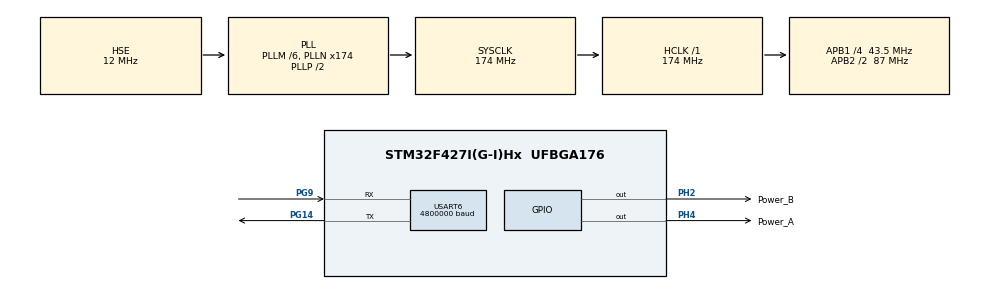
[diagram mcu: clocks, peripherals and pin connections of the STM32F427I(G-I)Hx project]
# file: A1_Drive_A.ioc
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Dma.Request0=USART6_TX
Dma.Request1=USART6_RX
Dma.USART6_RX.1.Direction=DMA_PERIPH_TO_MEMORY
Dma.USART6_RX.1.FIFOMode=DMA_FIFOMODE_DISABLE
Dma.USART6_RX.1.Instance=DMA2_Stream2
Dma.USART6_RX.1.MemDataAlignment=DMA_MDATAALIGN_BYTE
Dma.USART6_RX.1.MemInc=DMA_MINC_ENABLE
Dma.USART6_RX.1.Mode=DMA_CIRCULAR
Dma.USART6_RX.1.PeriphDataAlignment=DMA_PDATAALIGN_BYTE
Dma.USART6_RX.1.PeriphInc=DMA_PINC_DISABLE
Dma.USART6_RX.1.Priority=DMA_PRIORITY_VERY_HIGH
Dma.USART6_TX.0.Direction=DMA_MEMORY_TO_PERIPH
Dma.USART6_TX.0.FIFOMode=DMA_FIFOMODE_DISABLE
Dma.USART6_TX.0.Instance=DMA2_Stream7
Dma.USART6_TX.0.MemDataAlignment=DMA_MDATAALIGN_BYTE
Dma.USART6_TX.0.MemInc=DMA_MINC_ENABLE
Dma.USART6_TX.0.Mode=DMA_NORMAL
Dma.USART6_TX.0.PeriphDataAlignment=DMA_PDATAALIGN_BYTE
Dma.USART6_TX.0.PeriphInc=DMA_PINC_DISABLE
Dma.USART6_TX.0.Priority=DMA_PRIORITY_VERY_HIGH
Mcu.Family=STM32F4
Mcu.Name=STM32F427I(G-I)Hx
Mcu.Package=UFBGA176
NVIC.DMA2_Stream2_IRQn=true\:0\:0\:false\:false\:true\:false\:true
NVIC.DMA2_Stream7_IRQn=true\:0\:0\:false\:false\:true\:false\:true
NVIC.PriorityGroup=NVIC_PRIORITYGROUP_4
NVIC.USART6_IRQn=true\:0\:0\:false\:false\:false\:true\:true
PA13.Mode=Serial_Wire
PA13.Signal=SYS_JTMS-SWDIO
PA14.Mode=Serial_Wire
PA14.Signal=SYS_JTCK-SWCLK
PG14.Mode=Asynchronous
PG14.Signal=USART6_TX
PG9.Mode=Asynchronous
PG9.Signal=USART6_RX
PH0/OSC_IN.Mode=HSE-External-Oscillator
PH0/OSC_IN.Signal=RCC_OSC_IN
PH1/OSC_OUT.Mode=HSE-External-Oscillator
PH1/OSC_OUT.Signal=RCC_OSC_OUT
PH2.GPIO_Label=Power_B
PH2.Signal=GPIO_Output
PH4.GPIO_Label=Power_A
PH4.Signal=GPIO_Output
ProjectManager.HeapSize=0x200
ProjectManager.StackSize=0x400
ProjectManager.TargetToolchain=SW4STM32
RCC.48MHZClocksFreq_Value=87000000
RCC.AHBFreq_Value=174000000
RCC.APB1CLKDivider=RCC_HCLK_DIV4
RCC.APB1Freq_Value=43500000
RCC.APB1TimFreq_Value=87000000
RCC.APB2CLKDivider=RCC_HCLK_DIV2
RCC.APB2Freq_Value=87000000
RCC.APB2TimFreq_Value=174000000
RCC.CortexFreq_Value=174000000
RCC.HCLKFreq_Value=174000000
RCC.HSE_VALUE=12000000
RCC.HSI_VALUE=16000000
RCC.LSE_VALUE=32768
RCC.PLLM=6
RCC.PLLN=174
RCC.PLLSourceVirtual=RCC_PLLSOURCE_HSE
RCC.SYSCLKFreq_VALUE=174000000
RCC.SYSCLKSource=RCC_SYSCLKSOURCE_PLLCLK
RCC.VCOOutputFreq_Value=348000000
USART6.BaudRate=4800000
USART6.VirtualMode=VM_ASYNC
board=custom

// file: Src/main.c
/* USER CODE BEGIN Header */
/**
  ******************************************************************************
  * @file           : main.c
  * @brief          : Main program body
  ******************************************************************************
  * @attention
  *
  * Copyright (c) 2022 STMicroelectronics.
  * All rights reserved.
  *
  * This software is licensed under terms that can be found in the LICENSE file
  * in the root directory of this software component.
  * If no LICENSE file comes with this software, it is provided AS-IS.
  *
  ******************************************************************************
  */
/* USER CODE END Header */
#include "main.h"
#include "dma.h"
#include "usart.h"
#include "gpio.h"

/* USER CODE BEGIN Includes */
#include "A1_Drive.h"
/* USER CODE END Includes */

/* USER CODE BEGIN PV */
#pragma clang diagnostic push
#pragma ide diagnostic ignored "EndlessLoop"
/* USER CODE END PV */

void SystemClock_Config(void);

int main(void)
{

  /* MCU Configuration--------------------------------------------------------*/

  /* Reset of all peripherals, Initializes the Flash interface and the Systick. */
  HAL_Init();

  /* Configure the system clock */
  SystemClock_Config();

  /* Initialize all configured peripherals */
  MX_GPIO_Init();
  MX_DMA_Init();
  MX_USART6_UART_Init();
  /* USER CODE BEGIN 2 */
	Usart6_TX_DMA_Init();
	USART6_Rx_Init();
	HAL_GPIO_WritePin(Power_A_GPIO_Port,Power_A_Pin,GPIO_PIN_SET);
	HAL_GPIO_WritePin(Power_B_GPIO_Port,Power_B_Pin,GPIO_PIN_SET);
  /* USER CODE END 2 */

  /* Infinite loop */
  while (1)
  {

    /* USER CODE BEGIN 3 */
//		A1_Motor_Position_Control(0,3.14f);
//	A1_Motor_Speed_Control(0,3.0f);
//		HAL_Delay(10);
//		A1_Motor_Speed_Control(1,2);
//		A1_Motor_Multiple_Control(0,10,0.07f,0.5f,6.0f);
		HAL_Delay(1000);
  }
  /* USER CODE END 3 */
}

void SystemClock_Config(void)
{
  RCC_OscInitTypeDef RCC_OscInitStruct = {0};
  RCC_ClkInitTypeDef RCC_ClkInitStruct = {0};

  /** Configure the main internal regulator output voltage
  */
  __HAL_RCC_PWR_CLK_ENABLE();
  __HAL_PWR_VOLTAGESCALING_CONFIG(PWR_REGULATOR_VOLTAGE_SCALE1);
  /** Initializes the RCC Oscillators according to the specified parameters
  * in the RCC_OscInitTypeDef structure.
  */
  RCC_OscInitStruct.OscillatorType = RCC_OSCILLATORTYPE_HSE;
  RCC_OscInitStruct.HSEState = RCC_HSE_ON;
  RCC_OscInitStruct.PLL.PLLState = RCC_PLL_ON;
  RCC_OscInitStruct.PLL.PLLSource = RCC_PLLSOURCE_HSE;
  RCC_OscInitStruct.PLL.PLLM = 6;
  RCC_OscInitStruct.PLL.PLLN = 174;
  RCC_OscInitStruct.PLL.PLLP = RCC_PLLP_DIV2;
  RCC_OscInitStruct.PLL.PLLQ = 4;
  if (HAL_RCC_OscConfig(&RCC_OscInitStruct) != HAL_OK)
  {
    Error_Handler();
  }
  /** Activate the Over-Drive mode
  */
  if (HAL_PWREx_EnableOverDrive() != HAL_OK)
  {
    Error_Handler();
  }
  /** Initializes the CPU, AHB and APB buses clocks
  */
  RCC_ClkInitStruct.ClockType = RCC_CLOCKTYPE_HCLK|RCC_CLOCKTYPE_SYSCLK
                              |RCC_CLOCKTYPE_PCLK1|RCC_CLOCKTYPE_PCLK2;
  RCC_ClkInitStruct.SYSCLKSource = RCC_SYSCLKSOURCE_PLLCLK;
  RCC_ClkInitStruct.AHBCLKDivider = RCC_SYSCLK_DIV1;
  RCC_ClkInitStruct.APB1CLKDivider = RCC_HCLK_DIV4;
  RCC_ClkInitStruct.APB2CLKDivider = RCC_HCLK_DIV2;

  if (HAL_RCC_ClockConfig(&RCC_ClkInitStruct, FLASH_LATENCY_5) != HAL_OK)
  {
    Error_Handler();
  }
}

void Error_Handler(void)
{
  __disable_irq();
  while (1)
  {
  }
}
